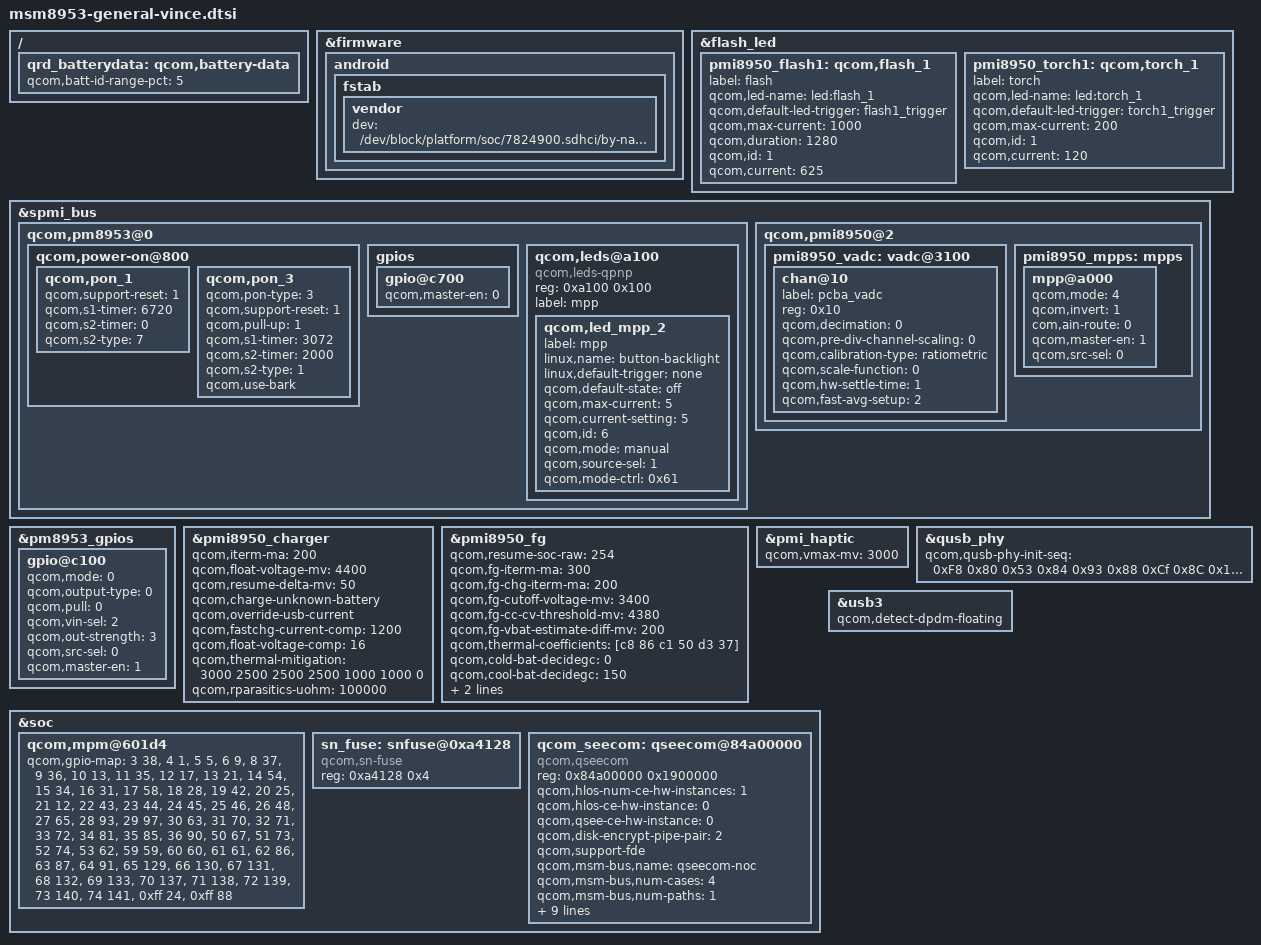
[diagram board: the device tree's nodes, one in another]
/* Copyright (c) 2017, The Linux Foundation. All rights reserved.
 *
 * This program is free software; you can redistribute it and/or modify
 * it under the terms of the GNU General Public License version 2 and
 * only version 2 as published by the Free Software Foundation.
 *
 * This program is distributed in the hope that it will be useful,
 * but WITHOUT ANY WARRANTY; without even the implied warranty of
 * MERCHANTABILITY or FITNESS FOR A PARTICULAR PURPOSE.  See the
 * GNU General Public License for more details.
 */

&firmware {
	android {
		fstab {
			vendor {
				dev = "/dev/block/platform/soc/7824900.sdhci/by-name/cust";
			};
		};
	};
};

&flash_led {
	pmi8950_flash1: qcom,flash_1 {
		label = "flash";
		qcom,led-name = "led:flash_1";
		qcom,default-led-trigger = "flash1_trigger";
		qcom,max-current = <1000>;
		qcom,duration = <1280>;
		qcom,id = <1>;
		qcom,current = <625>;
	};
	
	pmi8950_torch1: qcom,torch_1 {
		label = "torch";
		qcom,led-name = "led:torch_1";
		qcom,default-led-trigger = "torch1_trigger";
		qcom,max-current = <200>;
		qcom,id = <1>;
		qcom,current = <120>;
	};
};

&spmi_bus {
	qcom,pm8953@0 {
		qcom,power-on@800 {
			qcom,pon_1 {
				qcom,support-reset = <1>;
				qcom,s1-timer = <6720>;
				qcom,s2-timer = <0>;
				qcom,s2-type = <7>;
			};
			qcom,pon_3 {
				qcom,pon-type = <3>;
				qcom,support-reset = <1>;
				qcom,pull-up = <1>;
				qcom,s1-timer = <3072>;
				qcom,s2-timer = <2000>;
				qcom,s2-type = <1>;
				qcom,use-bark;
			};
		};
		gpios {
			gpio@c700 {
			qcom,master-en = <0>;/* disable this gpio */
			/delete-property/ status;
			};
		};
		qcom,leds@a100 {
			status = "okay";
			compatible = "qcom,leds-qpnp";
			reg = <0xa100 0x100>;
			label = "mpp";
			qcom,led_mpp_2 {
				label = "mpp";
				linux,name = "button-backlight";
				linux,default-trigger = "none";
				qcom,default-state = "off";
				qcom,max-current = <5>;
				qcom,current-setting = <5>;
				qcom,id = <6>;
				qcom,mode = "manual";
				qcom,source-sel = <1>;
				qcom,mode-ctrl = <0x61>;
			};
		};
		/delete-node/ qcom,pm8953_typec@bf00;
	};
};

&pm8953_gpios {
	/* GPIO 2 (NFC_CLK_REQ) */
	gpio@c100 {
		qcom,mode = <0>;
		qcom,output-type = <0>;
		qcom,pull = <0>;
		qcom,vin-sel = <2>;
		qcom,out-strength = <3>;
		qcom,src-sel = <0>;
		qcom,master-en = <1>;
		status = "okay";
	};
};

/ {
	qrd_batterydata: qcom,battery-data {
		qcom,batt-id-range-pct = <5>;
		#include "Vince-sunwoda-40Kohm-4000mah.dtsi"
		#include "Vince-desay-24Kohm-4000mAh.dtsi"
		#include "Vince-coslight-50Kohm-4000mah.dtsi"
		/delete-node/ qcom,qrd_msm8937_sku1_2920mah;
	};
};

&pmi8950_charger {
	qcom,iterm-ma = <200>; 
	qcom,float-voltage-mv = <4400>;
	qcom,resume-delta-mv = <50>;
	qcom,charge-unknown-battery;
	qcom,override-usb-current;
	qcom,fastchg-current-comp = <1200>;
	qcom,float-voltage-comp = <16>;
	qcom,thermal-mitigation = <3000 2500 2500 2500 1000 1000 0>;
	qcom,rparasitics-uohm = <100000>;
	/delete-property/ qcom,parallel-usb-min-current-ma;
	/delete-property/ qcom,parallel-usb-9v-min-current-ma;
	/delete-property/ qcom,parallel-allowed-lowering-ma;
	/delete-property/ qcom,chg-led-sw-controls;
	/delete-property/ qcom,chg-led-support;
	/delete-property/ qcom,external-typec;
	/delete-property/ qcom,typec-psy-name;
	/delete-property/ qcom,autoadjust-vfloat;
	/delete-property/ qcom,rparasitic-uohm;
};

&pmi8950_fg {
	qcom,resume-soc-raw = <254>;
 	qcom,fg-iterm-ma = <300>;
	qcom,fg-chg-iterm-ma = <200>; 
	qcom,fg-cutoff-voltage-mv = <3400>;
	qcom,fg-cc-cv-threshold-mv = <4380>;
	qcom,fg-vbat-estimate-diff-mv = <200>;
	qcom,thermal-coefficients = [c8 86 c1 50 d3 37];
	qcom,cold-bat-decidegc = <0>;
	qcom,cool-bat-decidegc = <150>;
	qcom,warm-bat-decidegc = <450>;
	qcom,fg-restore-batt-info;

};

&pmi_haptic {
	qcom,vmax-mv = <3000>;
};

&qusb_phy {
	qcom,qusb-phy-init-seq = <0xF8 0x80
					0x53 0x84 /* changed by xiaomi */
					0x93 0x88 /* changed by xiaomi */
					0xCf 0x8C /* changed by xiaomi */
					0x14 0x9C
					0x30 0x08
					0x79 0x0C
					0x21 0x10
					0x00 0x90
					0x9F 0x1C
					0x00 0x18>;
};

&soc {
	qcom,mpm@601d4 {
		qcom,gpio-map = <3  38 >,
			<4  1 >,
			<5  5 >,
			<6  9 >,
			<8  37>,
			<9  36>,
			<10  13>,
			<11  35>,
			<12  17>,
			<13  21>,
			<14  54>,
			<15  34>,
			<16  31>,
			<17  58>,
			<18  28>,
			<19  42>,
			<20  25>,
			<21  12>,
			<22  43>,
			<23  44>,
			<24  45>,
			<25  46>,
			<26  48>,
			<27  65>,
			<28  93>,
			<29  97>,
			<30  63>,
			<31  70>,
			<32  71>,
			<33  72>,
			<34  81>,
			<35  85>,
			<36  90>,
			<50  67>,
			<51  73>,
			<52  74>,
			<53  62>,
			<59  59>,
			<60  60>,
			<61  61>,
			<62  86>,
			<63  87>,
			<64  91>,
			<65  129>,
			<66  130>,
			<67  131>,
			<68  132>,
			<69  133>,
			<70  137>,
			<71  138>,
			<72  139>,
			<73  140>,
			<74  141>,
			<0xff  24>,
			<0xff 88>;
	};

	sn_fuse: snfuse@0xa4128 {
		compatible = "qcom,sn-fuse";
		reg = <0xa4128 0x4>;
		reg-names = "sn-base";
	};

	qcom_seecom: qseecom@84a00000 { /* renamed from caf qseecom@85b00000 */
                compatible = "qcom,qseecom";
                reg = <0x84a00000 0x1900000>; /* changed by xiaomi */
                reg-names = "secapp-region";
                qcom,hlos-num-ce-hw-instances = <1>;
                qcom,hlos-ce-hw-instance = <0>;
                qcom,qsee-ce-hw-instance = <0>;
                qcom,disk-encrypt-pipe-pair = <2>;
                qcom,support-fde;
                qcom,msm-bus,name = "qseecom-noc";
                qcom,msm-bus,num-cases = <4>;
                qcom,msm-bus,num-paths = <1>;
                qcom,support-bus-scaling;
                qcom,msm-bus,vectors-KBps =
                        <55 512 0 0>,
                        <55 512 0 0>,
                        <55 512 120000 1200000>,
                        <55 512 393600 3936000>;
                clocks = <&clock_gcc clk_crypto_clk_src>,
                         <&clock_gcc clk_gcc_crypto_clk>,
                         <&clock_gcc clk_gcc_crypto_ahb_clk>,
                         <&clock_gcc clk_gcc_crypto_axi_clk>;
                clock-names = "core_clk_src", "core_clk",
                                "iface_clk", "bus_clk";
                qcom,ce-opp-freq = <100000000>;
        };

};

&usb3 {
	qcom,detect-dpdm-floating;
};

&spmi_bus {
	qcom,pmi8950@2 {
		pmi8950_vadc: vadc@3100 {
			chan@10 {
				label = "pcba_vadc";
				reg = <0x10>;
				qcom,decimation = <0>;
				qcom,pre-div-channel-scaling = <0>; //1:1
				qcom,calibration-type = "ratiometric";
				qcom,scale-function = <0>;
				qcom,hw-settle-time = <1>;
				qcom,fast-avg-setup = <2>;
			};
		};
		pmi8950_mpps: mpps {
			mpp@a000 {
				qcom,mode = <4>; /* AIN input */
				qcom,invert = <1>; /* Enable MPP */
				com,ain-route = <0>; /* AMUX 5 */
				qcom,master-en = <1>;
				qcom,src-sel = <0>; /* Function constant */
				status = "okay";
			};
		};
	};
};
